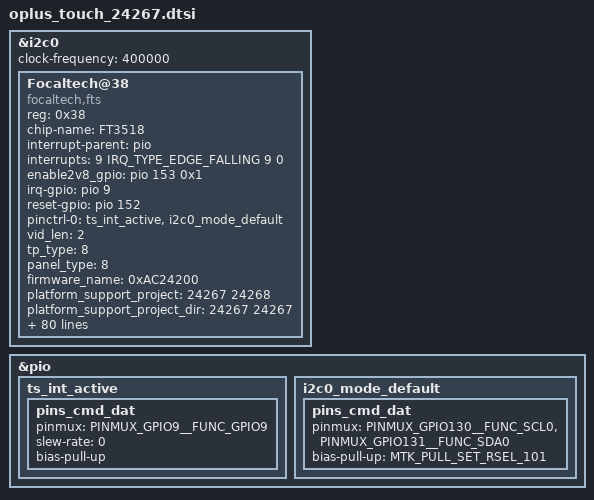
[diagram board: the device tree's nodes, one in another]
// SPDX-License-Identifier: (GPL-2.0 OR MIT)
/*
 * Copyright (C) 2020 MediaTek Inc.
 */
/* TOUCH start */

&i2c0 {
	status = "okay";
	clock-frequency = <400000>;

	Focaltech@38 {
		compatible = "focaltech,fts";
		reg = <0x38>;
		chip-name = "FT3518";
		status = "okay";

		/* Interrupt && Irq-gpio */
		interrupt-parent = <&pio>;
		interrupts = <9 IRQ_TYPE_EDGE_FALLING 9 0>;

		enable2v8_gpio = <&pio 153 0x1>;

		/* Other HW Resource */
		irq-gpio = <&pio 9 0x2002>;
		reset-gpio = <&pio 152 0>;
		pinctrl-names = "default";
		pinctrl-0 = <&ts_int_active &i2c0_mode_default>;

		vid_len = <2>;
		tp_type = <8>;
		// type of tp_dev ,TP-SAMSUNG = 8;
		panel_type = <8>;
		firmware_name = "0xAC24200";
		platform_support_project = <24267 24268>;
		platform_support_project_dir = <24267 24267>;
		platform_support_project_commandline = "default_commandline","default_commandline";
		touchpanel,max-num-support = <10>;
		touchpanel,tx-rx-num = <16 34>;
		touchpanel,panel-coords = <8640 19200>;
		touchpanel,display-coords = <1080 2400>;
		touchpanel,touchmajor-limit = <0 54>;
		touchpanel,report-rate = <120 180>;
		touchpanel,smooth-level = <255 2 15 25 45 60>;
		touchpanel,smooth-level-charging = <255 15 20 25 45 60>;
		touchpanel,sensitive-level = <255 20 17 14 10 8>;
		touchpanel,single-optimized-time = <8>;
		touchpanel,high-frame-rate-time = <20>;

		/* SW Support Feature Control */
		black_gesture_support;
		//fw_edge_limit_support;
		pressure_report_support;
		charger_pump_support;
		game_switch_support;
		smart_gesture_support;
		fw_update_app_support;
		fingerprint_underscreen_support;
		headset_pump_support;
		irq_need_dev_resume_ok;
		//esd_handle_support;
		high_resolution_support;
		health_monitor_support;
		disable_suspend_irq_handler_support;
		sportify_aod_gesture_support;
		black_gesture_indep_support;
		exception_upload_support;
		snr_read_support;
		kernel_grip_support;
		palm_to_sleep_support;
		high_resolution_support_x8;
		temperature_detect_shellback_support;
		fingerprint_not_report_in_suspend;
		glove_mode_v2_support;

		prevention,curved_screen_V2;
        prevention,grip_disable_level = <6>;
        prevention,updelay_time_ms = <30>;
        prevention,makeup_cnt_weight = <4 1 2 2 2>;
        prevention,large_corner_range = <960 2400>;
        prevention,large_corner_judge_condition = <500 300 800 7 7>;
        prevention,trx_reject_condition = <9 6 7>;
        prevention,trx_strict_reject_condition = <8 5 6>;
        prevention,large_judge_time_ms = <500 50 30>;
        prevention,large_exit_condition = <8 8 2>;
        prevention,single_channel_width = <160 160>;
        prevention,normal_tap_condition = <10 350>;
        prevention,long_edge_condition = <200 80 180 80>;
        prevention,long_strict_edge_condition = <160 60>;
        prevention,long_fingerhold_condition = <50 6 4 4>;
        prevention,short_edge_condition = <200 80 180 80>;
        prevention,short_strict_edge_condition = <160 60>;
        prevention,large_strict_exit_condition = <4 4>;
        prevention,top_corner_config = <440 1200 360>;
        prevention,edge_swipe_config = <240 960>;

        prevention,curved_screen_V4;
        prevention,long_eliminate_point_type = <2 8640 6400 240 19200 300 1>;
        prevention,long_fingerhold_condition2 = <420 0 0 0>;
        prevention,top_corner_config2 = <3 80 480 0 0>;
        prevention,hor_long_top_corner_config = <240 1600 0 0>;
        prevention,top_middle_config = <8640 800 800 0>;
        prevention,corner_eliminate_point_type = <0 960 1600 1>;
        prevention,finger_hold_differ_size = <1 0 240 300>;
        prevention,finger_hold_max_rx_exit_distance = <5 240 1600>;
        prevention,max_rx_exit_distance = <1 5 150 240 1600>;
        prevention,dynamic_finger_hold_exit_distance = <1 240 1600 360>;
        prevention,edge_sliding_matched_support = <1 150 3 0>;

        /* //grip v4.2 reclining mode
        prevention,reclining_mode_support = <1>;
        prevention,long_eliminate_point_type_recli = <2 8640 6400 80 19200 500 0>;
        prevention,finger_hold_differ_size_recli = <1 0 108 400>;
        prevention,finger_hold_max_rx_exit_distance_recli = <4 60 380>;
        prevention,max_rx_exit_distance_recli = <1 4 100 60 350>;
        prevention,dynamic_finger_hold_exit_distance_recli = <1 60 380 140>;
        prevention,edge_sliding_matched_support_recli = <1 200 3 0>; */

		/*
		 *Virtual Key Config:
		 *1:touchpanel,button-type: <virtualkey_type  supportted_button-map>
		 *virtualkey_type:
		 *Type 1: using board_properties
		 *Type 2: using same IC (button zone&& touch zone are seprate)
		 *Type 3: using diffrent IC (button zone&& touch zone are seprate)
		 *Type 4: No need of virtual key process
		 *supportted_button-map:select|menu|home|back
		 *
		 *2:touchpanel,button-map
		 *type (X1,Y1)(X2,Y2)(X3,Y3)(Width_X,Hight_Y)--Only when button-type is 0
		 */
		touchpanel,button-type = <4>;
		touchpanel.button-TRx = <0 0>;
	};
};
&pio {
	ts_int_active: ts_int_active {
		pins_cmd_dat {
			pinmux = <PINMUX_GPIO9__FUNC_GPIO9>;
			slew-rate = <0>;
			bias-pull-up;
		};
	};
	i2c0_mode_default: i2c0_mode_default {
	pins_cmd_dat {
		pinmux = <PINMUX_GPIO130__FUNC_SCL0>,
				 <PINMUX_GPIO131__FUNC_SDA0>;
			bias-pull-up = <MTK_PULL_SET_RSEL_101>;
		};
	};
};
